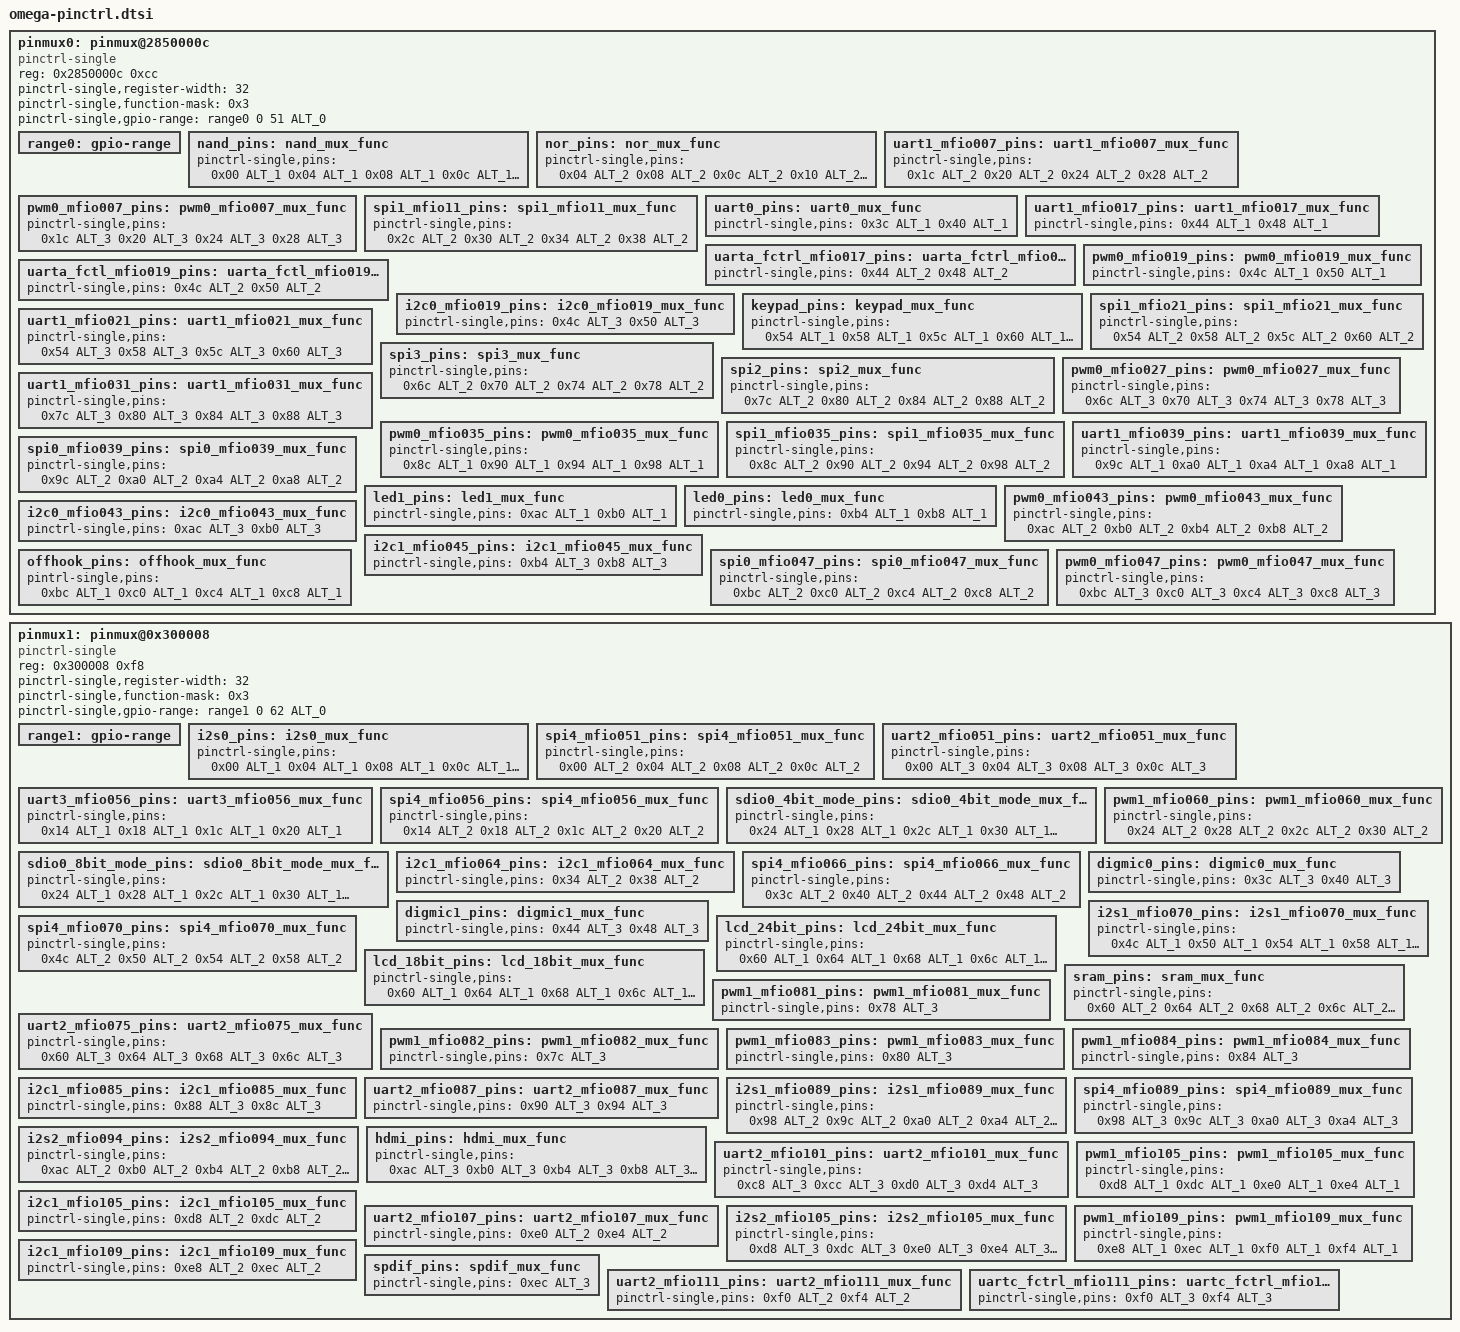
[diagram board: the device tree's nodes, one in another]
// SPDX-License-Identifier: (GPL-2.0 or BSD-3-Clause)
/*
 *  Copyright(c) 2018 Broadcom
 */

#include <dt-bindings/pinctrl/brcm,pinctrl-omega.h>

		pinmux0: pinmux@2850000c {
			compatible = "pinctrl-single";
			reg = <0x2850000c 0xcc>;
			#address-cells = <1>;
			#size-cells = <1>;
			#pinctrl-cells = <1>;
			pinctrl-single,register-width = <32>;
			pinctrl-single,function-mask = <0x3>;
			/* pin base, nr pins & gpio function */
			pinctrl-single,gpio-range = <
				&range0 0 51 ALT_0
				>;
			range0: gpio-range {
				#pinctrl-single,gpio-range-cells = <3>;
			};

			nand_pins: nand_mux_func {
				pinctrl-single,pins = <
					0x00 ALT_1  /* MFIO_000: NAND_ALE */
					0x04 ALT_1  /* MFIO_001: NAND_WE_B */
					0x08 ALT_1  /* MFIO_002: NAND_RE_B */
					0x0c ALT_1  /* MFIO_003: NAND_DQ0 */
					0x10 ALT_1  /* MFIO_004: NAND_DQ1 */
					0x14 ALT_1  /* MFIO_005: NAND_DQ2 */
					0x18 ALT_1  /* MFIO_006: NAND_DQ3 */
					0x1c ALT_1  /* MFIO_007: NAND_DQ4 */
					0x20 ALT_1  /* MFIO_008: NAND_DQ5 */
					0x24 ALT_1  /* MFIO_009: NAND_DQ6 */
					0x28 ALT_1  /* MFIO_010: NAND_DQ7 */
					0x2c ALT_1  /* MFIO_011: NAND_CLE */
					0x30 ALT_1  /* MFIO_012: NAND_CE_B */
					0x34 ALT_1  /* MFIO_013: NAND_RB_B */
					0x38 ALT_1  /* MFIO_014: NAND_WP_B */
				>;
			};

			nor_pins: nor_mux_func {
				pinctrl-single,pins = <
					0x04 ALT_2  /* MFIO_001: QSPI_WP_IO2 */
					0x08 ALT_2  /* MFIO_002: QSPI_HD_IO3 */
					0x0c ALT_2  /* MFIO_003: QSPI_CLK */
					0x10 ALT_2  /* MFIO_004: QSPI_CS */
					0x14 ALT_2  /* MFIO_005: QSPI_DI_IO0 */
					0x18 ALT_2  /* MFIO_006: QSPI_DO_IO1 */
				>;
			};

			uart1_mfio007_pins: uart1_mfio007_mux_func {
				pinctrl-single,pins = <
					0x1c ALT_2 /* MFIO_007: UART1_RX */
					0x20 ALT_2 /* MFIO_008: UART1_TX */
					0x24 ALT_2 /* MFIO_009: UARTB_RTS */
					0x28 ALT_2 /* MFIO_010: UARTB_CTS */
				>;
			};

			pwm0_mfio007_pins: pwm0_mfio007_mux_func {
				pinctrl-single,pins = <
					0x1c ALT_3 /* MFIO_007: PWM0_TM3 */
					0x20 ALT_3 /* MFIO_008: PWM0_TM2 */
					0x24 ALT_3 /* MFIO_009: PWM0_TM1 */
					0x28 ALT_3 /* MFIO_010: PWM0_TM0 */
				>;
			};

			spi1_mfio11_pins: spi1_mfio11_mux_func {
				pinctrl-single,pins = <
					0x2c ALT_2  /* MFIO_011: SPI1_SS */
					0x30 ALT_2  /* MFIO_012: SPI1_DIN */
					0x34 ALT_2  /* MFIO_013: SPI1_DOUT */
					0x38 ALT_2  /* MFIO_014: SPI1_CLK */
				>;
			};

			uart0_pins: uart0_mux_func {
				pinctrl-single,pins = <
					0x3c ALT_1 /* MFIO_015: UART0_RX */
					0x40 ALT_1 /* MFIO_016: UART0_TX */
				>;
			};

			uart1_mfio017_pins: uart1_mfio017_mux_func {
				pinctrl-single,pins = <
					0x44 ALT_1 /* MFIO_017: UART1_RX */
					0x48 ALT_1 /* MFIO_018: UART1_TX */
				>;
			};

			uarta_fctrl_mfio017_pins: uarta_fctrl_mfio017_mux_func {
				pinctrl-single,pins = <
					0x44 ALT_2 /* MFIO_017: UARTA_RTS */
					0x48 ALT_2 /* MFIO_018: UARTA_CTS */
				>;
			};

			pwm0_mfio019_pins: pwm0_mfio019_mux_func {
				pinctrl-single,pins = <
					0x4c ALT_1 /* MFIO_019: PWM0_TM3 */
					0x50 ALT_1 /* MFIO_020: PWM0_TM2 */
				>;
			};

			uarta_fctl_mfio019_pins: uarta_fctl_mfio019_mux_func {
				pinctrl-single,pins = <
					0x4c ALT_2 /* MFIO_019: UARTA_RTS */
					0x50 ALT_2 /* MFIO_020: UARTA_CTS */
				>;
			};

			i2c0_mfio019_pins: i2c0_mfio019_mux_func {
				pinctrl-single,pins = <
					0x4c ALT_3 /* MFIO_019: BSC0_SDA */
					0x50 ALT_3 /* MFIO_020: BSC0_SDA */
				>;
			};

			keypad_pins: keypad_mux_func {
				pinctrl-single,pins = <
					0x54 ALT_1 /* MFIO_021: KEY_0 */
					0x58 ALT_1 /* MFIO_022: KEY_1 */
					0x5c ALT_1 /* MFIO_023: KEY_2 */
					0x60 ALT_1 /* MFIO_024: KEY_3 */
					0x64 ALT_1 /* MFIO_025: KEY_4 */
					0x68 ALT_1 /* MFIO_026: KEY_5 */
					0x6c ALT_1 /* MFIO_027: KEY_6 */
					0x70 ALT_1 /* MFIO_028: KEY_7 */
					0x74 ALT_1 /* MFIO_029: KEY_8 */
					0x78 ALT_1 /* MFIO_030: KEY_9 */
					0x7c ALT_1 /* MFIO_031: KEY_10 */
					0x80 ALT_1 /* MFIO_032: KEY_11 */
					0x84 ALT_1 /* MFIO_033: KEY_12 */
					0x88 ALT_1 /* MFIO_034: KEY_13 */
				>;
			};

			spi1_mfio21_pins: spi1_mfio21_mux_func {
				pinctrl-single,pins = <
					0x54 ALT_2 /* MFIO_021: SPI1_SS */
					0x58 ALT_2 /* MFIO_022: SPI1_DIN */
					0x5c ALT_2 /* MFIO_023: SPI1_DOUT */
					0x60 ALT_2 /* MFIO_024: SPI1_SCLK */
				>;
			};

			uart1_mfio021_pins: uart1_mfio021_mux_func {
				pinctrl-single,pins = <
					0x54 ALT_3 /* MFIO_021: UART1_RX */
					0x58 ALT_3 /* MFIO_022: UART1_TX */
					0x5c ALT_3 /* MFIO_023: UARTB_RTS */
					0x60 ALT_3 /* MFIO_024: UARTB_CTS */
				>;
			};

			spi3_pins: spi3_mux_func {
				pinctrl-single,pins = <
					0x6c ALT_2 /* MFIO_027: SPI3_SS */
					0x70 ALT_2 /* MFIO_028: SPI3_DIN */
					0x74 ALT_2 /* MFIO_029: SPI3_DOUT */
					0x78 ALT_2 /* MFIO_030: SPI3_SCLK */
				>;
			};

			spi2_pins: spi2_mux_func {
				pinctrl-single,pins = <
					0x7c ALT_2 /* MFIO_031: SPI2_SS */
					0x80 ALT_2 /* MFIO_032: SPI2_DIN */
					0x84 ALT_2 /* MFIO_033: SPI2_DOUT */
					0x88 ALT_2 /* MFIO_034: SPI2_SCLK */
				>;
			};

			pwm0_mfio027_pins: pwm0_mfio027_mux_func {
				pinctrl-single,pins = <
					0x6c ALT_3 /* MFIO_027: PWM0_TM3 */
					0x70 ALT_3 /* MFIO_028: PWM0_TM2 */
					0x74 ALT_3 /* MFIO_029: PWM0_TM1 */
					0x78 ALT_3 /* MFIO_030: PWM0_TM0 */
				>;
			};

			uart1_mfio031_pins: uart1_mfio031_mux_func {
				pinctrl-single,pins = <
					0x7c ALT_3 /* MFIO_031: UART1_RX */
					0x80 ALT_3 /* MFIO_032: UART1_TX */
					0x84 ALT_3 /* MFIO_033: UARTB_RTS */
					0x88 ALT_3 /* MFIO_034: UARTB_CTS */
				>;
			};

			pwm0_mfio035_pins: pwm0_mfio035_mux_func {
				pinctrl-single,pins = <
					0x8c ALT_1 /* MFIO_035: PWM0_TM3 */
					0x90 ALT_1 /* MFIO_036: PWM0_TM2 */
					0x94 ALT_1 /* MFIO_037: PWM0_TM1 */
					0x98 ALT_1 /* MFIO_038: PWM0_TM0 */
				>;
			};

			spi1_mfio035_pins: spi1_mfio035_mux_func {
				pinctrl-single,pins = <
					0x8c ALT_2 /* MFIO_035: SPI1_SS */
					0x90 ALT_2 /* MFIO_036: SPI1_DIN */
					0x94 ALT_2 /* MFIO_037: SPI1_DOUT */
					0x98 ALT_2 /* MFIO_038: SPI1_SCLK */
				>;
			};

			uart1_mfio039_pins: uart1_mfio039_mux_func {
				pinctrl-single,pins = <
					0x9c ALT_1 /* MFIO_039: UART1_RX */
					0xa0 ALT_1 /* MFIO_040: UART1_TX */
					0xa4 ALT_1 /* MFIO_041: UARTB_RTS */
					0xa8 ALT_1 /* MFIO_042: UARTB_CTS */
				>;
			};

			spi0_mfio039_pins: spi0_mfio039_mux_func {
				pinctrl-single,pins = <
					0x9c ALT_2 /* MFIO_039: SPI0_SS */
					0xa0 ALT_2 /* MFIO_040: SPI0_DIN */
					0xa4 ALT_2 /* MFIO_041: SPI0_DOUT */
					0xa8 ALT_2 /* MFIO_042: SPI0_SCLK */
				>;
			};

			led1_pins: led1_mux_func {
				pinctrl-single,pins = <
					0xac ALT_1 /* MFIO_043 LED1_LNKSPD */
					0xb0 ALT_1 /* MFIO_044 LED1_ACT */
				>;
			};

			led0_pins: led0_mux_func {
				pinctrl-single,pins = <
					0xb4 ALT_1 /* MFIO_045 LED0_LNKSPD */
					0xb8 ALT_1 /* MFIO_046 LED0_ACT */
				>;
			};

			pwm0_mfio043_pins: pwm0_mfio043_mux_func {
				pinctrl-single,pins = <
					0xac ALT_2 /* MFIO_043: PWM0_TM3 */
					0xb0 ALT_2 /* MFIO_044: PWM0_TM2 */
					0xb4 ALT_2 /* MFIO_045: PWM0_TM1 */
					0xb8 ALT_2 /* MFIO_046: PWM0_TM0 */
				>;
			};

			i2c0_mfio043_pins: i2c0_mfio043_mux_func {
				pinctrl-single,pins = <
					0xac ALT_3 /* MFIO_043: BSC0_SDA */
					0xb0 ALT_3 /* MFIO_044: BSC0_SDA */
				>;
			};

			i2c1_mfio045_pins: i2c1_mfio045_mux_func {
				pinctrl-single,pins = <
					0xb4 ALT_3 /* MFIO_045: BSC1_SDA */
					0xb8 ALT_3 /* MFIO_046: BSC1_SDA */
				>;
			};

			offhook_pins: offhook_mux_func {
				pintrl-single,pins = <
					0xbc ALT_1 /* MFIO_047: MUTE_IN */
					0xc0 ALT_1 /* MFIO_048: MUTE_LED */
					0xc4 ALT_1 /* MFIO_049: OFF_HOOK_IN */
					0xc8 ALT_1 /* MFIO_050: ACTIVE_LED */
				>;
			};

			spi0_mfio047_pins: spi0_mfio047_mux_func {
				pinctrl-single,pins = <
					0xbc ALT_2 /* MFIO_047: SPI0_SS */
					0xc0 ALT_2 /* MFIO_048: SPI0_DIN */
					0xc4 ALT_2 /* MFIO_049: SPI0_DOUT */
					0xc8 ALT_2 /* MFIO_050: SPI0_SCLK */
				>;
			};

			pwm0_mfio047_pins: pwm0_mfio047_mux_func {
				pinctrl-single,pins = <
					0xbc ALT_3 /* MFIO_047: PWM0_TM3 */
					0xc0 ALT_3 /* MFIO_048: PWM0_TM2 */
					0xc4 ALT_3 /* MFIO_049: PWM0_TM1 */
					0xc8 ALT_3 /* MFIO_050: PWM0_TM0 */
				>;
			};
		};


		pinmux1: pinmux@0x300008 {
			compatible = "pinctrl-single";
			reg = <0x300008 0xf8>;
			#address-cells = <1>;
			#size-cells = <1>;
			#pinctrl-cells = <1>;
			pinctrl-single,register-width = <32>;
			pinctrl-single,function-mask = <0x3>;

			/* pin base, nr pins & gpio function */
			pinctrl-single,gpio-range = <
				&range1 0 62 ALT_0
				>;
			range1: gpio-range {
				#pinctrl-single,gpio-range-cells = <3>;
			};

			i2s0_pins: i2s0_mux_func {
				pinctrl-single,pins = <
					0x00 ALT_1 /* MFIO_051: I2S0_BCLK */
					0x04 ALT_1 /* MFIO_052: I2S0_WS */
					0x08 ALT_1 /* MFIO_053: I2S0_DOUT */
					0x0c ALT_1 /* MFIO_054: I2S0_DIN */
					0x10 ALT_1 /* MFIO_055: I2S0_MCLK */
				>;
			};

			spi4_mfio051_pins: spi4_mfio051_mux_func {
				pinctrl-single,pins = <
					0x00 ALT_2  /* MFIO_051: SPI4_SS */
					0x04 ALT_2  /* MFIO_052: SPI4_DIN */
					0x08 ALT_2  /* MFIO_053: SPI4_DOUT */
					0x0c ALT_2  /* MFIO_054: SPI4_CLK */
				>;
			};

			uart2_mfio051_pins: uart2_mfio051_mux_func {
				pinctrl-single,pins = <
					0x00 ALT_3 /* MFIO_051: UART2_RX */
					0x04 ALT_3 /* MFIO_052: UART2_TX */
					0x08 ALT_3 /* MFIO_053: UARTC_RTS */
					0x0c ALT_3 /* MFIO_054: UARTC_CTS */
				>;
			};

			uart3_mfio056_pins: uart3_mfio056_mux_func {
				pinctrl-single,pins = <
					0x14 ALT_1 /* MFIO_056: UART3_RX */
					0x18 ALT_1 /* MFIO_057: UART3_TX */
					0x1c ALT_1 /* MFIO_058: UARTD_RTS */
					0x20 ALT_1 /* MFIO_059: UARTD_CTS */
				>;
			};

			spi4_mfio056_pins: spi4_mfio056_mux_func {
				pinctrl-single,pins = <
					0x14 ALT_2  /* MFIO_056: SPI4_SS */
					0x18 ALT_2  /* MFIO_057: SPI4_DIN */
					0x1c ALT_2  /* MFIO_058: SPI4_DOUT */
					0x20 ALT_2  /* MFIO_059: SPI4_CLK */
				>;
			};

			sdio0_4bit_mode_pins: sdio0_4bit_mode_mux_func {
				pinctrl-single,pins = <
					0x24 ALT_1 /* MFIO_060: SDIO_CLK */
					0x28 ALT_1 /* MFIO_061: SDIO_CMD */
					0x2c ALT_1 /* MFIO_062: SDIO_D0 */
					0x30 ALT_1 /* MFIO_063: SDIO_D1 */
					0x34 ALT_1 /* MFIO_064: SDIO_D2 */
					0x38 ALT_1 /* MFIO_065: SDIO_D3 */
				>;
			};

			sdio0_8bit_mode_pins: sdio0_8bit_mode_mux_func {
				pinctrl-single,pins = <
					0x24 ALT_1 /* MFIO_060: SDIO_CLK */
					0x28 ALT_1 /* MFIO_061: SDIO_CMD */
					0x2c ALT_1 /* MFIO_062: SDIO_D0 */
					0x30 ALT_1 /* MFIO_063: SDIO_D1 */
					0x34 ALT_1 /* MFIO_064: SDIO_D2 */
					0x38 ALT_1 /* MFIO_065: SDIO_D3 */
					0x3c ALT_1 /* MFIO_066: SDIO_D4 */
					0x40 ALT_1 /* MFIO_067: SDIO_D5 */
					0x44 ALT_1 /* MFIO_068: SDIO_D6 */
					0x48 ALT_1 /* MFIO_069: SDIO_D7 */
				>;
			};

			pwm1_mfio060_pins: pwm1_mfio060_mux_func {
				pinctrl-single,pins = <
					0x24 ALT_2 /* MFIO_060: PWM1_TM3 */
					0x28 ALT_2 /* MFIO_061: PWM1_TM2 */
					0x2c ALT_2 /* MFIO_062: PWM1_TM1 */
					0x30 ALT_2 /* MFIO_063: PWM1_TM0 */
				>;
			};

			i2c1_mfio064_pins: i2c1_mfio064_mux_func {
				pinctrl-single,pins = <
					0x34 ALT_2 /* MFIO_064: BSC1_SDA */
					0x38 ALT_2 /* MFIO_065: BSC1_SDA */
				>;
			};

			spi4_mfio066_pins: spi4_mfio066_mux_func {
				pinctrl-single,pins = <
					0x3c ALT_2  /* MFIO_066: SPI4_SS */
					0x40 ALT_2  /* MFIO_067: SPI4_DIN */
					0x44 ALT_2  /* MFIO_068: SPI4_DOUT */
					0x48 ALT_2  /* MFIO_069: SPI4_CLK */
				>;
			};

			digmic0_pins: digmic0_mux_func {
				pinctrl-single,pins = <
					0x3c ALT_3 /* MFIO_066: DMIC0_CLK */
					0x40 ALT_3 /* MFIO_067: DMIC0_DAT */
				>;
			};

			digmic1_pins: digmic1_mux_func {
				pinctrl-single,pins = <
					0x44 ALT_3 /* MFIO_068: DMIC1_CLK */
					0x48 ALT_3 /* MFIO_069: DMIC1_DAT */
				>;
			};

			i2s1_mfio070_pins: i2s1_mfio070_mux_func {
				pinctrl-single,pins = <
					0x4c ALT_1 /* MFIO_070: I2S1_BCLK */
					0x50 ALT_1 /* MFIO_071: I2S1_WS */
					0x54 ALT_1 /* MFIO_072: I2S1_DOUT */
					0x58 ALT_1 /* MFIO_073: I2S1_DIN */
					0x5c ALT_1 /* MFIO_074: I2S1_MCLK */
				>;
			};

			spi4_mfio070_pins: spi4_mfio070_mux_func {
				pinctrl-single,pins = <
					0x4c ALT_2  /* MFIO_070: SPI4_SS */
					0x50 ALT_2  /* MFIO_071: SPI4_DIN */
					0x54 ALT_2  /* MFIO_072: SPI4_DOUT */
					0x58 ALT_2  /* MFIO_073: SPI4_CLK */
				>;
			};

			lcd_24bit_pins: lcd_24bit_mux_func {
				pinctrl-single,pins = <
					0x60 ALT_1 /* MFIO_075: LCD_CLCP */
					0x64 ALT_1 /* MFIO_076: LCD_CLPOWER */
					0x68 ALT_1 /* MFIO_077: LCD_CLLE */
					0x6c ALT_1 /* MFIO_078: LCD_CLFP */
					0x70 ALT_1 /* MFIO_079: LCD_CLLP */
					0x74 ALT_1 /* MFIO_080: LCD_CLAC */
					0x78 ALT_1 /* MFIO_081: LCD_CLD0 */
					0x7c ALT_1 /* MFIO_082: LCD_CLD1 */
					0x80 ALT_1 /* MFIO_083: LCD_CLD2 */
					0x84 ALT_1 /* MFIO_084: LCD_CLD3 */
					0x88 ALT_1 /* MFIO_085: LCD_CLD4 */
					0x8c ALT_1 /* MFIO_086: LCD_CLD5 */
					0x90 ALT_1 /* MFIO_087: LCD_CLD6 */
					0x94 ALT_1 /* MFIO_088: LCD_CLD7 */
					0x98 ALT_1 /* MFIO_089: LCD_CLD8 */
					0x9c ALT_1 /* MFIO_090: LCD_CLD9 */
					0xa0 ALT_1 /* MFIO_091: LCD_CLD10 */
					0xa4 ALT_1 /* MFIO_092: LCD_CLD11 */
					0xa8 ALT_1 /* MFIO_093: LCD_CLD12 */
					0xac ALT_1 /* MFIO_094: LCD_CLD13 */
					0xb0 ALT_1 /* MFIO_095: LCD_CLD14 */
					0xb4 ALT_1 /* MFIO_096: LCD_CLD15 */
					0xb8 ALT_1 /* MFIO_097: LCD_CLD16 */
					0xbc ALT_1 /* MFIO_098: LCD_CLD17 */
					0xc0 ALT_1 /* MFIO_099: LCD_CLD18 */
					0xc4 ALT_1 /* MFIO_100: LCD_CLD19 */
					0xc8 ALT_1 /* MFIO_101: LCD_CLD20 */
					0xcc ALT_1 /* MFIO_102: LCD_CLD21 */
					0xd0 ALT_1 /* MFIO_103: LCD_CLD22 */
					0xd4 ALT_1 /* MFIO_104: LCD_CLD23 */
				>;
			};

			lcd_18bit_pins: lcd_18bit_mux_func {
				pinctrl-single,pins = <
					0x60 ALT_1 /* MFIO_075: LCD_CLCP */
					0x64 ALT_1 /* MFIO_076: LCD_CLPOWER */
					0x68 ALT_1 /* MFIO_077: LCD_CLLE */
					0x6c ALT_1 /* MFIO_078: LCD_CLFP */
					0x70 ALT_1 /* MFIO_079: LCD_CLLP */
					0x74 ALT_1 /* MFIO_080: LCD_CLAC */
					0x80 ALT_1 /* MFIO_083: LCD_CLD2 */
					0x84 ALT_1 /* MFIO_084: LCD_CLD3 */
					0x88 ALT_1 /* MFIO_085: LCD_CLD4 */
					0x8c ALT_1 /* MFIO_086: LCD_CLD5 */
					0x90 ALT_1 /* MFIO_087: LCD_CLD6 */
					0x94 ALT_1 /* MFIO_088: LCD_CLD7 */
					0xa0 ALT_1 /* MFIO_091: LCD_CLD10 */
					0xa4 ALT_1 /* MFIO_092: LCD_CLD11 */
					0xa8 ALT_1 /* MFIO_093: LCD_CLD12 */
					0xac ALT_1 /* MFIO_094: LCD_CLD13 */
					0xb0 ALT_1 /* MFIO_095: LCD_CLD14 */
					0xb4 ALT_1 /* MFIO_096: LCD_CLD15 */
					0xc0 ALT_1 /* MFIO_099: LCD_CLD18 */
					0xc4 ALT_1 /* MFIO_100: LCD_CLD19 */
					0xc8 ALT_1 /* MFIO_101: LCD_CLD20 */
					0xcc ALT_1 /* MFIO_102: LCD_CLD21 */
					0xd0 ALT_1 /* MFIO_103: LCD_CLD22 */
					0xd4 ALT_1 /* MFIO_104: LCD_CLD23 */
				>;
			};

			sram_pins: sram_mux_func {
				pinctrl-single,pins = <
					0x60 ALT_2 /* MFIO_075: SRAM_A2 */
					0x64 ALT_2 /* MFIO_076: SRAM_A1 */
					0x68 ALT_2 /* MFIO_077: SRAM_A0 */
					0x6c ALT_2 /* MFIO_078: SRAM_RD_B */
					0x70 ALT_2 /* MFIO_079: SRAM_WE_B */
					0x74 ALT_2 /* MFIO_080: SRAM_CS_B */
					0x78 ALT_2 /* MFIO_081: SRAM_D0 */
					0x7c ALT_2 /* MFIO_082: SRAM_D1 */
					0x80 ALT_2 /* MFIO_083: SRAM_D2 */
					0x84 ALT_2 /* MFIO_084: SRAM_D3 */
					0x88 ALT_2 /* MFIO_085: SRAM_D4 */
					0x8c ALT_2 /* MFIO_086: SRAM_D5 */
					0x90 ALT_2 /* MFIO_087: SRAM_D6 */
					0x94 ALT_2 /* MFIO_088: SRAM_D7 */
				>;
			};

			uart2_mfio075_pins: uart2_mfio075_mux_func {
				pinctrl-single,pins = <
					0x60 ALT_3 /* MFIO_075: UART2_RX */
					0x64 ALT_3 /* MFIO_076: UART2_TX */
					0x68 ALT_3 /* MFIO_077: UARTC_RTS */
					0x6c ALT_3 /* MFIO_078: UARTC_CTS */
				>;
			};

			pwm1_mfio081_pins: pwm1_mfio081_mux_func {
				pinctrl-single,pins = <
					0x78 ALT_3 /* MFIO_081: PWM1_TM3 */
				>;
			};

			pwm1_mfio082_pins: pwm1_mfio082_mux_func {
				pinctrl-single,pins = <
					0x7c ALT_3 /* MFIO_082: PWM1_TM2 */
				>;
			};

			pwm1_mfio083_pins: pwm1_mfio083_mux_func {
				pinctrl-single,pins = <
					0x80 ALT_3 /* MFIO_083: PWM1_TM1 */
				>;
			};

			pwm1_mfio084_pins: pwm1_mfio084_mux_func {
				pinctrl-single,pins = <
					0x84 ALT_3 /* MFIO_084: PWM1_TM0 */
				>;
			};

			i2c1_mfio085_pins: i2c1_mfio085_mux_func {
				pinctrl-single,pins = <
					0x88 ALT_3 /* MFIO_085: BSC1_SDA */
					0x8c ALT_3 /* MFIO_086: BSC1_SDA */
				>;
			};

			uart2_mfio087_pins: uart2_mfio087_mux_func {
				pinctrl-single,pins = <
					0x90 ALT_3 /* MFIO_087: UART2_RX */
					0x94 ALT_3 /* MFIO_088: UART2_TX */
				>;
			};

			i2s1_mfio089_pins: i2s1_mfio089_mux_func {
				pinctrl-single,pins = <
					0x98 ALT_2 /* MFIO_089: I2S1_BCLK */
					0x9c ALT_2 /* MFIO_090: I2S1_WS */
					0xa0 ALT_2 /* MFIO_091: I2S1_DOUT */
					0xa4 ALT_2 /* MFIO_092: I2S1_DIN */
					0xa8 ALT_2 /* MFIO_093: I2S1_MCLK */
				>;
			};

			spi4_mfio089_pins: spi4_mfio089_mux_func {
				pinctrl-single,pins = <
					0x98 ALT_3  /* MFIO_089: SPI4_SS */
					0x9c ALT_3  /* MFIO_090: SPI4_DIN */
					0xa0 ALT_3  /* MFIO_091: SPI4_DOUT */
					0xa4 ALT_3  /* MFIO_092: SPI4_CLK */
				>;
			};

			i2s2_mfio094_pins: i2s2_mfio094_mux_func {
				pinctrl-single,pins = <
					0xac ALT_2 /* MFIO_094: I2S2_BCLK */
					0xb0 ALT_2 /* MFIO_095: I2S2_WS */
					0xb4 ALT_2 /* MFIO_096: I2S2_DOUT */
					0xb8 ALT_2 /* MFIO_097: I2S2_DIN */
					0xbc ALT_2 /* MFIO_098: I2S2_MCLK */
				>;
			};

			hdmi_pins: hdmi_mux_func {
				pinctrl-single,pins = <
					0xac ALT_3 /* MFIO_094: HBR_BCLK */
					0xb0 ALT_3 /* MFIO_095: HBR_WS */
					0xb4 ALT_3 /* MFIO_096: HBR_DIN0 */
					0xb8 ALT_3 /* MFIO_097: HBR_DIN1 */
					0xbc ALT_3 /* MFIO_098: HBR_MCLK */
					0xc0 ALT_3 /* MFIO_099: HBR_DIN2 */
					0xc4 ALT_3 /* MFIO_100: HBR_DIN3 */
				>;
			};

			uart2_mfio101_pins: uart2_mfio101_mux_func {
				pinctrl-single,pins = <
					0xc8 ALT_3 /* MFIO_101: UART2_RX */
					0xcc ALT_3 /* MFIO_102: UART2_TX */
					0xd0 ALT_3 /* MFIO_103: UARTC_RTS */
					0xd4 ALT_3 /* MFIO_104: UARTC_CTS */
				>;
			};

			pwm1_mfio105_pins: pwm1_mfio105_mux_func {
				pinctrl-single,pins = <
					0xd8 ALT_1 /* MFIO_105: PWM1_TM3 */
					0xdc ALT_1 /* MFIO_106: PWM1_TM2 */
					0xe0 ALT_1 /* MFIO_107: PWM1_TM1 */
					0xe4 ALT_1 /* MFIO_108: PWM1_TM0 */
				>;
			};

			i2c1_mfio105_pins: i2c1_mfio105_mux_func {
				pinctrl-single,pins = <
					0xd8 ALT_2 /* MFIO_105: BSC1_SDA */
					0xdc ALT_2 /* MFIO_106: BSC1_SDA */
				>;
			};

			uart2_mfio107_pins: uart2_mfio107_mux_func {
				pinctrl-single,pins = <
					0xe0 ALT_2 /* MFIO_107: UART2_RX */
					0xe4 ALT_2 /* MFIO_108: UART2_TX */
				>;
			};

			i2s2_mfio105_pins: i2s2_mfio105_mux_func {
				pinctrl-single,pins = <
					0xd8 ALT_3 /* MFIO_105: I2S2_BCLK */
					0xdc ALT_3 /* MFIO_106: I2S2_WS */
					0xe0 ALT_3 /* MFIO_107: I2S2_DOUT */
					0xe4 ALT_3 /* MFIO_108: I2S2_DIN */
					0xe8 ALT_3 /* MFIO_109: I2S2_MCLK */
				>;
			};

			pwm1_mfio109_pins: pwm1_mfio109_mux_func {
				pinctrl-single,pins = <
					0xe8 ALT_1 /* MFIO_109: PWM1_TM3 */
					0xec ALT_1 /* MFIO_110: PWM1_TM2 */
					0xf0 ALT_1 /* MFIO_111: PWM1_TM1 */
					0xf4 ALT_1 /* MFIO_112: PWM1_TM0 */
				>;
			};

			i2c1_mfio109_pins: i2c1_mfio109_mux_func {
				pinctrl-single,pins = <
					0xe8 ALT_2 /* MFIO_109: BSC1_SDA */
					0xec ALT_2 /* MFIO_110: BSC1_SDA */
				>;
			};

			spdif_pins: spdif_mux_func {
				pinctrl-single,pins = <
					0xec ALT_3 /* MFIO_110: SPDIF_OUT0 */
				>;
			};

			uart2_mfio111_pins: uart2_mfio111_mux_func {
				pinctrl-single,pins = <
					0xf0 ALT_2 /* MFIO_111: UART2_RX */
					0xf4 ALT_2 /* MFIO_112: UART2_TX */
				>;
			};

			uartc_fctrl_mfio111_pins: uartc_fctrl_mfio111_mux_func {
				pinctrl-single,pins = <
					0xf0 ALT_3 /* MFIO_111: UARTC_RTS */
					0xf4 ALT_3 /* MFIO_112: UARTC_CTS */
				>;
			};
		};




